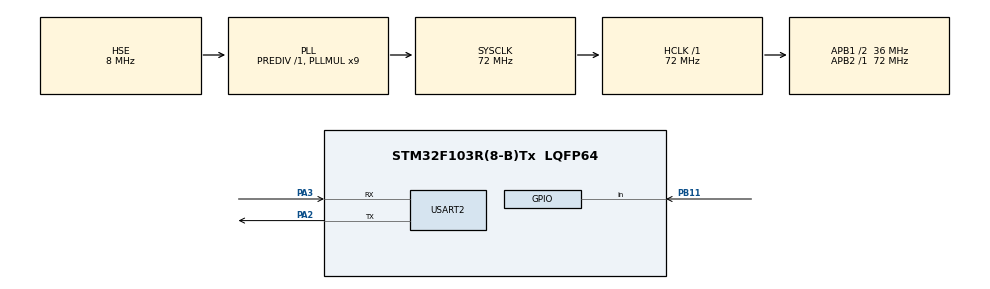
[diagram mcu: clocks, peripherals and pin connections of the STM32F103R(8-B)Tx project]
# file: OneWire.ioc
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Mcu.Family=STM32F1
Mcu.Name=STM32F103R(8-B)Tx
Mcu.Package=LQFP64
NVIC.PriorityGroup=NVIC_PRIORITYGROUP_4
PA13.Mode=Serial_Wire
PA13.Signal=SYS_JTMS-SWDIO
PA14.Mode=Serial_Wire
PA14.Signal=SYS_JTCK-SWCLK
PA2.Mode=Asynchronous
PA2.Signal=USART2_TX
PA3.Mode=Asynchronous
PA3.Signal=USART2_RX
PB11.Signal=GPIO_Input
PD0-OSC_IN.Mode=HSE-External-Oscillator
PD0-OSC_IN.Signal=RCC_OSC_IN
PD1-OSC_OUT.Mode=HSE-External-Oscillator
PD1-OSC_OUT.Signal=RCC_OSC_OUT
ProjectManager.HeapSize=0x200
ProjectManager.StackSize=0x400
ProjectManager.TargetToolchain=MDK-ARM V5
RCC.AHBFreq_Value=72000000
RCC.APB1CLKDivider=RCC_HCLK_DIV2
RCC.APB1Freq_Value=36000000
RCC.APB1TimFreq_Value=72000000
RCC.APB2Freq_Value=72000000
RCC.APB2TimFreq_Value=72000000
RCC.HCLKFreq_Value=72000000
RCC.PLLMUL=RCC_PLL_MUL9
RCC.PLLSourceVirtual=RCC_PLLSOURCE_HSE
RCC.SYSCLKFreq_VALUE=72000000
RCC.SYSCLKSource=RCC_SYSCLKSOURCE_PLLCLK
RCC.USBFreq_Value=72000000
USART2.VirtualMode=VM_ASYNC
board=OneWire

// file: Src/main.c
/**
  ******************************************************************************
  * File Name          : main.c
  * Description        : Main program body
  ******************************************************************************
  ** This notice applies to any and all portions of this file
  * that are not between comment pairs USER CODE BEGIN and
  * USER CODE END. Other portions of this file, whether
  * inserted by the user or by software development tools
  * are owned by their respective copyright owners.
  *
  * COPYRIGHT(c) 2018 STMicroelectronics
  *
  * Redistribution and use in source and binary forms, with or without modification,
  * are permitted provided that the following conditions are met:
  *   1. Redistributions of source code must retain the above copyright notice,
  *      this list of conditions and the following disclaimer.
  *   2. Redistributions in binary form must reproduce the above copyright notice,
  *      this list of conditions and the following disclaimer in the documentation
  *      and/or other materials provided with the distribution.
  *   3. Neither the name of STMicroelectronics nor the names of its contributors
  *      may be used to endorse or promote products derived from this software
  *      without specific prior written permission.
  *
  * THIS SOFTWARE IS PROVIDED BY THE COPYRIGHT HOLDERS AND CONTRIBUTORS "AS IS"
  * AND ANY EXPRESS OR IMPLIED WARRANTIES, INCLUDING, BUT NOT LIMITED TO, THE
  * IMPLIED WARRANTIES OF MERCHANTABILITY AND FITNESS FOR A PARTICULAR PURPOSE ARE
  * DISCLAIMED. IN NO EVENT SHALL THE COPYRIGHT HOLDER OR CONTRIBUTORS BE LIABLE
  * FOR ANY DIRECT, INDIRECT, INCIDENTAL, SPECIAL, EXEMPLARY, OR CONSEQUENTIAL
  * DAMAGES (INCLUDING, BUT NOT LIMITED TO, PROCUREMENT OF SUBSTITUTE GOODS OR
  * SERVICES; LOSS OF USE, DATA, OR PROFITS; OR BUSINESS INTERRUPTION) HOWEVER
  * CAUSED AND ON ANY THEORY OF LIABILITY, WHETHER IN CONTRACT, STRICT LIABILITY,
  * OR TORT (INCLUDING NEGLIGENCE OR OTHERWISE) ARISING IN ANY WAY OUT OF THE USE
  * OF THIS SOFTWARE, EVEN IF ADVISED OF THE POSSIBILITY OF SUCH DAMAGE.
  *
  ******************************************************************************
  */

#include "main.h"
#include "stm32f1xx_hal.h"

/* USER CODE BEGIN Includes */
#include "ds18b20.h"
/* USER CODE END Includes */

UART_HandleTypeDef huart2;

/* USER CODE BEGIN PV */
/* Private variables ---------------------------------------------------------*/
char str1[64];
/* USER CODE END PV */

void SystemClock_Config(void);
static void MX_GPIO_Init(void);
static void MX_USART2_UART_Init(void);

/* USER CODE BEGIN PFP */
/* Private function prototypes -----------------------------------------------*/

/* USER CODE END PFP */

int main(void)
{

  /* USER CODE BEGIN 1 */
	uint8_t status;
	uint8_t dt[8];
	uint8_t RAW_DATA[32];
	uint16_t raw_temper;
	float temper;
	char c;
  /* USER CODE END 1 */

  /* MCU Configuration----------------------------------------------------------*/

  /* Reset of all peripherals, Initializes the Flash interface and the Systick. */
  HAL_Init();

  /* Configure the system clock */
  SystemClock_Config();

  /* Initialize all configured peripherals */
  MX_GPIO_Init();
  MX_USART2_UART_Init();

  /* USER CODE BEGIN 2 */
	port_init();
	status = ds18b20_init(SKIP_ROM);
	sprintf(str1,"Init Status: %d\r\n",status);
	HAL_UART_Transmit(&huart2,(uint8_t*)str1,strlen(str1),0x1000);
  /* USER CODE END 2 */

  /* Infinite loop */
  while (1)
  {

  /* USER CODE BEGIN 3 */
	HAL_Delay(100);
	port_init();
//	status = ds18b20_init(SKIP_ROM);
//	sprintf(str1,"Init Status: %d\r\n",status);
//	HAL_UART_Transmit(&huart2,(uint8_t*)str1,strlen(str1),0x1000);
//
//	ds18b20_MeasureTemperCmd(SKIP_ROM, 0);
//	HAL_Delay(800);
	ds2502_Read_MAC(dt);
//	sprintf(str1,"STRATHPAD: %02X %02X %02X %02X %02X %02X %02X %02X; ",
//	dt[0], dt[1], dt[2], dt[3], dt[4], dt[5], dt[6], dt[7]);
//	HAL_UART_Transmit(&huart2,(uint8_t*)str1,strlen(str1),0x1000);
//	raw_temper = ((uint16_t)dt[1]<<8)|dt[0];
//	if(ds18b20_GetSign(raw_temper)) c='-';
//	else c='+';
//	temper = ds18b20_Convert(raw_temper);
//	sprintf(str1,"Raw t: 0x%04X; t: %c%.2f\r\n", raw_temper, c, temper);
//	HAL_UART_Transmit(&huart2,(uint8_t*)str1,strlen(str1),0x1000);
	//HAL_Delay(200);

	ds2502_Read_ID(RAW_DATA);
//	ds2502_wrire();
  }
  /* USER CODE END 3 */

}

/** System Clock Configuration
*/
void SystemClock_Config(void)
{

  RCC_OscInitTypeDef RCC_OscInitStruct;
  RCC_ClkInitTypeDef RCC_ClkInitStruct;

    /**Initializes the CPU, AHB and APB busses clocks
    */
  RCC_OscInitStruct.OscillatorType = RCC_OSCILLATORTYPE_HSE;
  RCC_OscInitStruct.HSEState = RCC_HSE_ON;
  RCC_OscInitStruct.HSEPredivValue = RCC_HSE_PREDIV_DIV1;
  RCC_OscInitStruct.HSIState = RCC_HSI_ON;
  RCC_OscInitStruct.PLL.PLLState = RCC_PLL_ON;
  RCC_OscInitStruct.PLL.PLLSource = RCC_PLLSOURCE_HSE;
  RCC_OscInitStruct.PLL.PLLMUL = RCC_PLL_MUL9;
  if (HAL_RCC_OscConfig(&RCC_OscInitStruct) != HAL_OK)
  {
    _Error_Handler(__FILE__, __LINE__);
  }

    /**Initializes the CPU, AHB and APB busses clocks
    */
  RCC_ClkInitStruct.ClockType = RCC_CLOCKTYPE_HCLK|RCC_CLOCKTYPE_SYSCLK
                              |RCC_CLOCKTYPE_PCLK1|RCC_CLOCKTYPE_PCLK2;
  RCC_ClkInitStruct.SYSCLKSource = RCC_SYSCLKSOURCE_PLLCLK;
  RCC_ClkInitStruct.AHBCLKDivider = RCC_SYSCLK_DIV1;
  RCC_ClkInitStruct.APB1CLKDivider = RCC_HCLK_DIV2;
  RCC_ClkInitStruct.APB2CLKDivider = RCC_HCLK_DIV1;

  if (HAL_RCC_ClockConfig(&RCC_ClkInitStruct, FLASH_LATENCY_2) != HAL_OK)
  {
    _Error_Handler(__FILE__, __LINE__);
  }

    /**Configure the Systick interrupt time
    */
  HAL_SYSTICK_Config(HAL_RCC_GetHCLKFreq()/1000);

    /**Configure the Systick
    */
  HAL_SYSTICK_CLKSourceConfig(SYSTICK_CLKSOURCE_HCLK);

  /* SysTick_IRQn interrupt configuration */
  HAL_NVIC_SetPriority(SysTick_IRQn, 0, 0);
}

/* USART2 init function */
static void MX_USART2_UART_Init(void)
{

  huart2.Instance = USART2;
  huart2.Init.BaudRate = 115200;
  huart2.Init.WordLength = UART_WORDLENGTH_8B;
  huart2.Init.StopBits = UART_STOPBITS_1;
  huart2.Init.Parity = UART_PARITY_NONE;
  huart2.Init.Mode = UART_MODE_TX_RX;
  huart2.Init.HwFlowCtl = UART_HWCONTROL_NONE;
  huart2.Init.OverSampling = UART_OVERSAMPLING_16;
  if (HAL_UART_Init(&huart2) != HAL_OK)
  {
    _Error_Handler(__FILE__, __LINE__);
  }

}

/** Configure pins as
        * Analog
        * Input
        * Output
        * EVENT_OUT
        * EXTI
*/
static void MX_GPIO_Init(void)
{

  GPIO_InitTypeDef GPIO_InitStruct;

  /* GPIO Ports Clock Enable */
  __HAL_RCC_GPIOD_CLK_ENABLE();
  __HAL_RCC_GPIOA_CLK_ENABLE();
  __HAL_RCC_GPIOB_CLK_ENABLE();

  /*Configure GPIO pin : PB11 */
  GPIO_InitStruct.Pin = GPIO_PIN_11;
  GPIO_InitStruct.Mode = GPIO_MODE_INPUT;
  GPIO_InitStruct.Pull = GPIO_NOPULL;
  HAL_GPIO_Init(GPIOB, &GPIO_InitStruct);

}

void _Error_Handler(char * file, int line)
{
  while(1)
  {
  }
}

/************************ (C) COPYRIGHT STMicroelectronics *****END OF FILE****/
